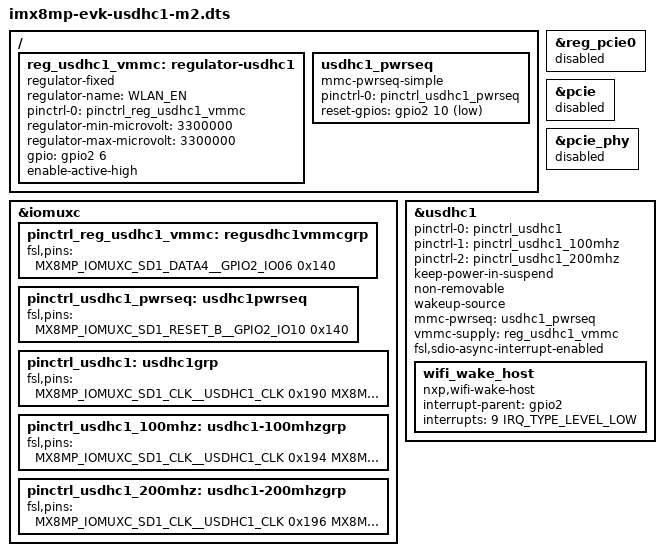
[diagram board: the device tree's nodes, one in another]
// SPDX-License-Identifier: (GPL-2.0 OR MIT)
/*
 * Copyright 2021 NXP
 */

#include "imx8mp-evk.dts"

/ {
	reg_usdhc1_vmmc: regulator-usdhc1 {
		compatible = "regulator-fixed";
		regulator-name = "WLAN_EN";
		pinctrl-names = "default";
		pinctrl-0 = <&pinctrl_reg_usdhc1_vmmc>;
		regulator-min-microvolt = <3300000>;
		regulator-max-microvolt = <3300000>;
		gpio = <&gpio2 6 GPIO_ACTIVE_HIGH>;
		enable-active-high;
	};

	usdhc1_pwrseq: usdhc1_pwrseq {
		compatible = "mmc-pwrseq-simple";
		pinctrl-names = "default";
		pinctrl-0 = <&pinctrl_usdhc1_pwrseq>;
		reset-gpios = <&gpio2 10 GPIO_ACTIVE_LOW>;
	};
};

&iomuxc {
	pinctrl_reg_usdhc1_vmmc: regusdhc1vmmcgrp {
		fsl,pins = <
			MX8MP_IOMUXC_SD1_DATA4__GPIO2_IO06	0x140
		>;
	};

	pinctrl_usdhc1_pwrseq: usdhc1pwrseq {
		fsl,pins = <
			MX8MP_IOMUXC_SD1_RESET_B__GPIO2_IO10	0x140
		>;
	};

	pinctrl_usdhc1: usdhc1grp {
		fsl,pins = <
			MX8MP_IOMUXC_SD1_CLK__USDHC1_CLK	0x190
			MX8MP_IOMUXC_SD1_CMD__USDHC1_CMD	0x1d0
			MX8MP_IOMUXC_SD1_DATA0__USDHC1_DATA0	0x1d0
			MX8MP_IOMUXC_SD1_DATA1__USDHC1_DATA1	0x1d0
			MX8MP_IOMUXC_SD1_DATA2__USDHC1_DATA2	0x1d0
			MX8MP_IOMUXC_SD1_DATA3__USDHC1_DATA3	0x1d0
		>;
	};

	pinctrl_usdhc1_100mhz: usdhc1-100mhzgrp {
		fsl,pins = <
			MX8MP_IOMUXC_SD1_CLK__USDHC1_CLK	0x194
			MX8MP_IOMUXC_SD1_CMD__USDHC1_CMD	0x1d4
			MX8MP_IOMUXC_SD1_DATA0__USDHC1_DATA0	0x1d4
			MX8MP_IOMUXC_SD1_DATA1__USDHC1_DATA1	0x1d4
			MX8MP_IOMUXC_SD1_DATA2__USDHC1_DATA2	0x1d4
			MX8MP_IOMUXC_SD1_DATA3__USDHC1_DATA3	0x1d4
		>;
	};

	pinctrl_usdhc1_200mhz: usdhc1-200mhzgrp {
		fsl,pins = <
			MX8MP_IOMUXC_SD1_CLK__USDHC1_CLK	0x196
			MX8MP_IOMUXC_SD1_CMD__USDHC1_CMD	0x1d6
			MX8MP_IOMUXC_SD1_DATA0__USDHC1_DATA0	0x1d6
			MX8MP_IOMUXC_SD1_DATA1__USDHC1_DATA1	0x1d6
			MX8MP_IOMUXC_SD1_DATA2__USDHC1_DATA2	0x1d6
			MX8MP_IOMUXC_SD1_DATA3__USDHC1_DATA3	0x1d6
		>;
	};
};

&reg_pcie0 {
	status = "disabled";
};

&pcie {
	status = "disabled";
	/delete-node/ wifi_wake_host;
};

&pcie_phy {
	status = "disabled";
};

&usdhc1 {
	pinctrl-names = "default", "state_100mhz", "state_200mhz";
	pinctrl-0 = <&pinctrl_usdhc1>;
	pinctrl-1 = <&pinctrl_usdhc1_100mhz>;
	pinctrl-2 = <&pinctrl_usdhc1_200mhz>;
	keep-power-in-suspend;
	non-removable;
	wakeup-source;
	mmc-pwrseq = <&usdhc1_pwrseq>;
	vmmc-supply = <&reg_usdhc1_vmmc>;
	fsl,sdio-async-interrupt-enabled;
	status = "okay";

	wifi_wake_host {
		compatible = "nxp,wifi-wake-host";
		interrupt-parent = <&gpio2>;
		interrupts = <9 IRQ_TYPE_LEVEL_LOW>;
		interrupt-names = "host-wake";
	};
};
